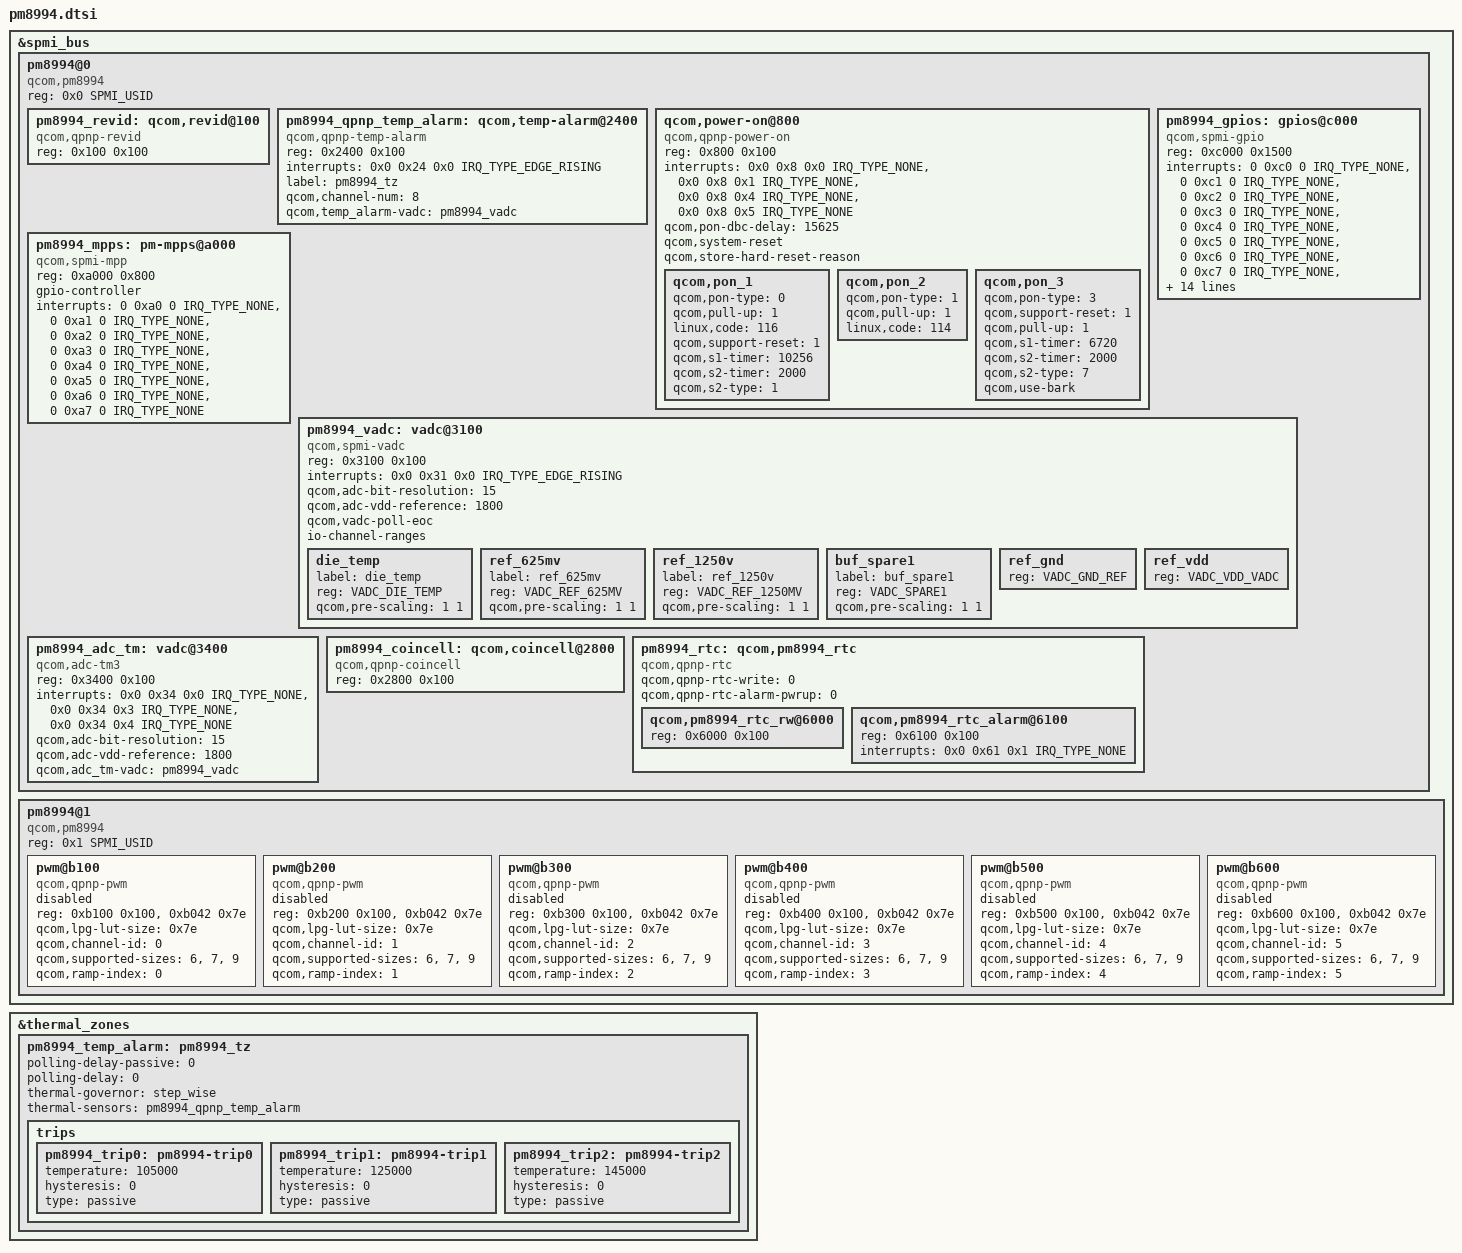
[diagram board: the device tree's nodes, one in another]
#include <dt-bindings/interrupt-controller/irq.h>
#include <dt-bindings/spmi/spmi.h>
#include <dt-bindings/iio/qcom,spmi-vadc.h>

&spmi_bus {

	pm8994@0 {
		compatible = "qcom,pm8994", "qcom,spmi-pmic";
		reg = <0x0 SPMI_USID>;
		#address-cells = <2>;
		#size-cells = <0>;

		pm8994_revid: qcom,revid@100 {
			compatible = "qcom,qpnp-revid";
			reg = <0x100 0x100>;
		};

		pm8994_qpnp_temp_alarm: qcom,temp-alarm@2400 {
			compatible = "qcom,qpnp-temp-alarm";
			reg = <0x2400 0x100>;
			interrupts = <0x0 0x24 0x0 IRQ_TYPE_EDGE_RISING>;
			label = "pm8994_tz";
			qcom,channel-num = <8>;
			qcom,temp_alarm-vadc = <&pm8994_vadc>;
			#thermal-sensor-cells = <0>;
		};

		qcom,power-on@800 {
			compatible = "qcom,qpnp-power-on";
			reg = <0x800 0x100>;
			interrupts = <0x0 0x8 0x0 IRQ_TYPE_NONE>,
				     <0x0 0x8 0x1 IRQ_TYPE_NONE>,
				     <0x0 0x8 0x4 IRQ_TYPE_NONE>,
				     <0x0 0x8 0x5 IRQ_TYPE_NONE>;
			interrupt-names = "kpdpwr", "resin",
					"resin-bark", "kpdpwr-resin-bark";
			qcom,pon-dbc-delay = <15625>;
			qcom,system-reset;
			qcom,store-hard-reset-reason;

			qcom,pon_1 {
				qcom,pon-type = <0>;
				qcom,pull-up = <1>;
				linux,code = <116>;
				qcom,support-reset = <1>;
				qcom,s1-timer = <10256>;
				qcom,s2-timer = <2000>;
				qcom,s2-type = <1>;
			};

			qcom,pon_2 {
				qcom,pon-type = <1>;
				qcom,pull-up = <1>;
				linux,code = <114>;
			};

			qcom,pon_3 {
				qcom,pon-type = <3>;
				qcom,support-reset = <1>;
				qcom,pull-up = <1>;
				qcom,s1-timer = <6720>;
				qcom,s2-timer = <2000>;
				qcom,s2-type = <7>;
				qcom,use-bark;
			};
		};

		pm8994_gpios: gpios@c000 {
			compatible = "qcom,spmi-gpio";
			reg = <0xc000 0x1500>;
			interrupts = <0 0xc0 0 IRQ_TYPE_NONE>,
				     <0 0xc1 0 IRQ_TYPE_NONE>,
				     <0 0xc2 0 IRQ_TYPE_NONE>,
				     <0 0xc3 0 IRQ_TYPE_NONE>,
				     <0 0xc4 0 IRQ_TYPE_NONE>,
				     <0 0xc5 0 IRQ_TYPE_NONE>,
				     <0 0xc6 0 IRQ_TYPE_NONE>,
				     <0 0xc7 0 IRQ_TYPE_NONE>,
				     <0 0xc8 0 IRQ_TYPE_NONE>,
				     <0 0xc9 0 IRQ_TYPE_NONE>,
				     <0 0xca 0 IRQ_TYPE_NONE>,
				     <0 0xcb 0 IRQ_TYPE_NONE>,
				     <0 0xcc 0 IRQ_TYPE_NONE>,
				     <0 0xcd 0 IRQ_TYPE_NONE>,
				     <0 0xce 0 IRQ_TYPE_NONE>,
				     <0 0xd0 0 IRQ_TYPE_NONE>,
				     <0 0xd1 0 IRQ_TYPE_NONE>,
				     <0 0xd2 0 IRQ_TYPE_NONE>,
				     <0 0xd3 0 IRQ_TYPE_NONE>,
				     <0 0xd4 0 IRQ_TYPE_NONE>,
				     <0 0xd5 0 IRQ_TYPE_NONE>;
			interrupt-names = "pm8994_gpio1", "pm8994_gpio2",
					"pm8994_gpio3",
					"pm8994_gpio4", "pm8994_gpio5",
					"pm8994_gpio6", "pm8994_gpio7",
					"pm8994_gpio8", "pm8994_gpio9",
					"pm8994_gpio10", "pm8994_gpio11",
					"pm8994_gpio12", "pm8994_gpio13",
					"pm8994_gpio14", "pm8994_gpio15",
					"pm8994_gpio16", "pm8994_gpio17",
					"pm8994_gpio18", "pm8994_gpio19",
					"pm8994_gpio20", "pm8994_gpio21",
					"pm8994_gpio22";
			gpio-controller;
			#gpio-cells = <2>;
		};

		pm8994_mpps: pm-mpps@a000 {
			compatible = "qcom,spmi-mpp";
			reg = <0xa000 0x800>;
			gpio-controller;
			#gpio-cells = <2>;
			interrupts = <0 0xa0 0 IRQ_TYPE_NONE>,
				     <0 0xa1 0 IRQ_TYPE_NONE>,
				     <0 0xa2 0 IRQ_TYPE_NONE>,
				     <0 0xa3 0 IRQ_TYPE_NONE>,
				     <0 0xa4 0 IRQ_TYPE_NONE>,
				     <0 0xa5 0 IRQ_TYPE_NONE>,
				     <0 0xa6 0 IRQ_TYPE_NONE>,
				     <0 0xa7 0 IRQ_TYPE_NONE>;
			interrupt-names = "pm8994_mpp1", "pm8994_mpp2",
					  "pm8994_mpp3", "pm8994_mpp4",
					  "pm8994_mpp5", "pm8994_mpp6",
					  "pm8994_mpp7", "pm8994_mpp8";
		};

		pm8994_vadc: vadc@3100 {
			compatible = "qcom,spmi-vadc";
			reg = <0x3100 0x100>;
			#address-cells = <1>;
			#size-cells = <0>;
			interrupts = <0x0 0x31 0x0 IRQ_TYPE_EDGE_RISING>;
			interrupt-names = "eoc-int-en-set";
			qcom,adc-bit-resolution = <15>;
			qcom,adc-vdd-reference = <1800>;
			qcom,vadc-poll-eoc;
			#thermal-sensor-cells = <1>;
			#io-channel-cells = <1>;
			io-channel-ranges;

			die_temp {
				label = "die_temp";
				reg = <VADC_DIE_TEMP>;
				qcom,pre-scaling = <1 1>;
			};

			ref_625mv {
				label = "ref_625mv";
				reg = <VADC_REF_625MV>;
				qcom,pre-scaling = <1 1>;
			};

			ref_1250v {
				label = "ref_1250v";
				reg = <VADC_REF_1250MV>;
				qcom,pre-scaling = <1 1>;
			};

			buf_spare1 {
				label = "buf_spare1";
				reg = <VADC_SPARE1>;
				qcom,pre-scaling = <1 1>;
			};

			ref_gnd {
				reg = <VADC_GND_REF>;
			};
			ref_vdd {
				reg = <VADC_VDD_VADC>;
			};
		};

		pm8994_adc_tm: vadc@3400 {
			compatible = "qcom,adc-tm3";
			reg = <0x3400 0x100>;
			#address-cells = <1>;
			#size-cells = <0>;
			#thermal-sensor-cells = <1>;
			interrupts =	<0x0 0x34 0x0 IRQ_TYPE_NONE>,
					<0x0 0x34 0x3 IRQ_TYPE_NONE>,
				     <0x0 0x34 0x4 IRQ_TYPE_NONE>;
			interrupt-names =	"eoc-int-en-set",
						"high-thr-en-set",
						"low-thr-en-set";
			qcom,adc-bit-resolution = <15>;
			qcom,adc-vdd-reference = <1800>;
			qcom,adc_tm-vadc = <&pm8994_vadc>;
		};

		pm8994_coincell: qcom,coincell@2800 {
			compatible = "qcom,qpnp-coincell";
			reg = <0x2800 0x100>;
		};

		pm8994_rtc: qcom,pm8994_rtc {
			compatible = "qcom,qpnp-rtc";
			#address-cells = <1>;
			#size-cells = <1>;
			qcom,qpnp-rtc-write = <0>;
			qcom,qpnp-rtc-alarm-pwrup = <0>;

			qcom,pm8994_rtc_rw@6000 {
				reg = <0x6000 0x100>;
			};
			qcom,pm8994_rtc_alarm@6100 {
				reg = <0x6100 0x100>;
				interrupts = <0x0 0x61 0x1 IRQ_TYPE_NONE>;
			};
		};
	};

	pm8994@1 {
		compatible = "qcom,pm8994", "qcom,spmi-pmic";
		reg = <0x1 SPMI_USID>;
		#address-cells = <2>;
		#size-cells = <0>;

		pwm@b100 {
			compatible = "qcom,qpnp-pwm";
			reg = <0xb100 0x100>,
			      <0xb042 0x7e>;
			reg-names = "qpnp-lpg-channel-base", "qpnp-lpg-lut-base";
			qcom,lpg-lut-size = <0x7e>;
			qcom,channel-id = <0>;
			qcom,supported-sizes = <6>, <7>, <9>;
			qcom,ramp-index = <0>;
			#pwm-cells = <2>;
			status = "disabled";
		};

		pwm@b200 {
			compatible = "qcom,qpnp-pwm";
			reg = <0xb200 0x100>,
			      <0xb042 0x7e>;
			reg-names = "qpnp-lpg-channel-base", "qpnp-lpg-lut-base";
			qcom,lpg-lut-size = <0x7e>;
			qcom,channel-id = <1>;
			qcom,supported-sizes = <6>, <7>, <9>;
			qcom,ramp-index = <1>;
			#pwm-cells = <2>;
			status = "disabled";
		};

		pwm@b300 {
			compatible = "qcom,qpnp-pwm";
			reg = <0xb300 0x100>,
			      <0xb042 0x7e>;
			reg-names = "qpnp-lpg-channel-base", "qpnp-lpg-lut-base";
			qcom,lpg-lut-size = <0x7e>;
			qcom,channel-id = <2>;
			qcom,supported-sizes = <6>, <7>, <9>;
			qcom,ramp-index = <2>;
			#pwm-cells = <2>;
			status = "disabled";
		};

		pwm@b400 {
			compatible = "qcom,qpnp-pwm";
			reg = <0xb400 0x100>,
			      <0xb042 0x7e>;
			reg-names = "qpnp-lpg-channel-base", "qpnp-lpg-lut-base";
			qcom,lpg-lut-size = <0x7e>;
			qcom,channel-id = <3>;
			qcom,supported-sizes = <6>, <7>, <9>;
			qcom,ramp-index = <3>;
			#pwm-cells = <2>;
			status = "disabled";
		};

		pwm@b500 {
			compatible = "qcom,qpnp-pwm";
			reg = <0xb500 0x100>,
			      <0xb042 0x7e>;
			reg-names = "qpnp-lpg-channel-base", "qpnp-lpg-lut-base";
			qcom,lpg-lut-size = <0x7e>;
			qcom,channel-id = <4>;
			qcom,supported-sizes = <6>, <7>, <9>;
			qcom,ramp-index = <4>;
			#pwm-cells = <2>;
			status = "disabled";
		};

		pwm@b600 {
			compatible = "qcom,qpnp-pwm";
			reg = <0xb600 0x100>,
			      <0xb042 0x7e>;
			reg-names = "qpnp-lpg-channel-base", "qpnp-lpg-lut-base";
			qcom,lpg-lut-size = <0x7e>;
			qcom,channel-id = <5>;
			qcom,supported-sizes = <6>, <7>, <9>;
			qcom,ramp-index = <5>;
			#pwm-cells = <2>;
			status = "disabled";
		};
	};
};

&thermal_zones {
	pm8994_temp_alarm: pm8994_tz {
		polling-delay-passive = <0>;
		polling-delay = <0>;
		thermal-governor = "step_wise";
		thermal-sensors = <&pm8994_qpnp_temp_alarm>;

		trips {
			pm8994_trip0: pm8994-trip0 {
				temperature = <105000>;
				hysteresis = <0>;
				type = "passive";
			};
			pm8994_trip1: pm8994-trip1 {
				temperature = <125000>;
				hysteresis = <0>;
				type = "passive";
			};
			pm8994_trip2: pm8994-trip2 {
				temperature = <145000>;
				hysteresis = <0>;
				type = "passive";
			};
		};
	};
};
